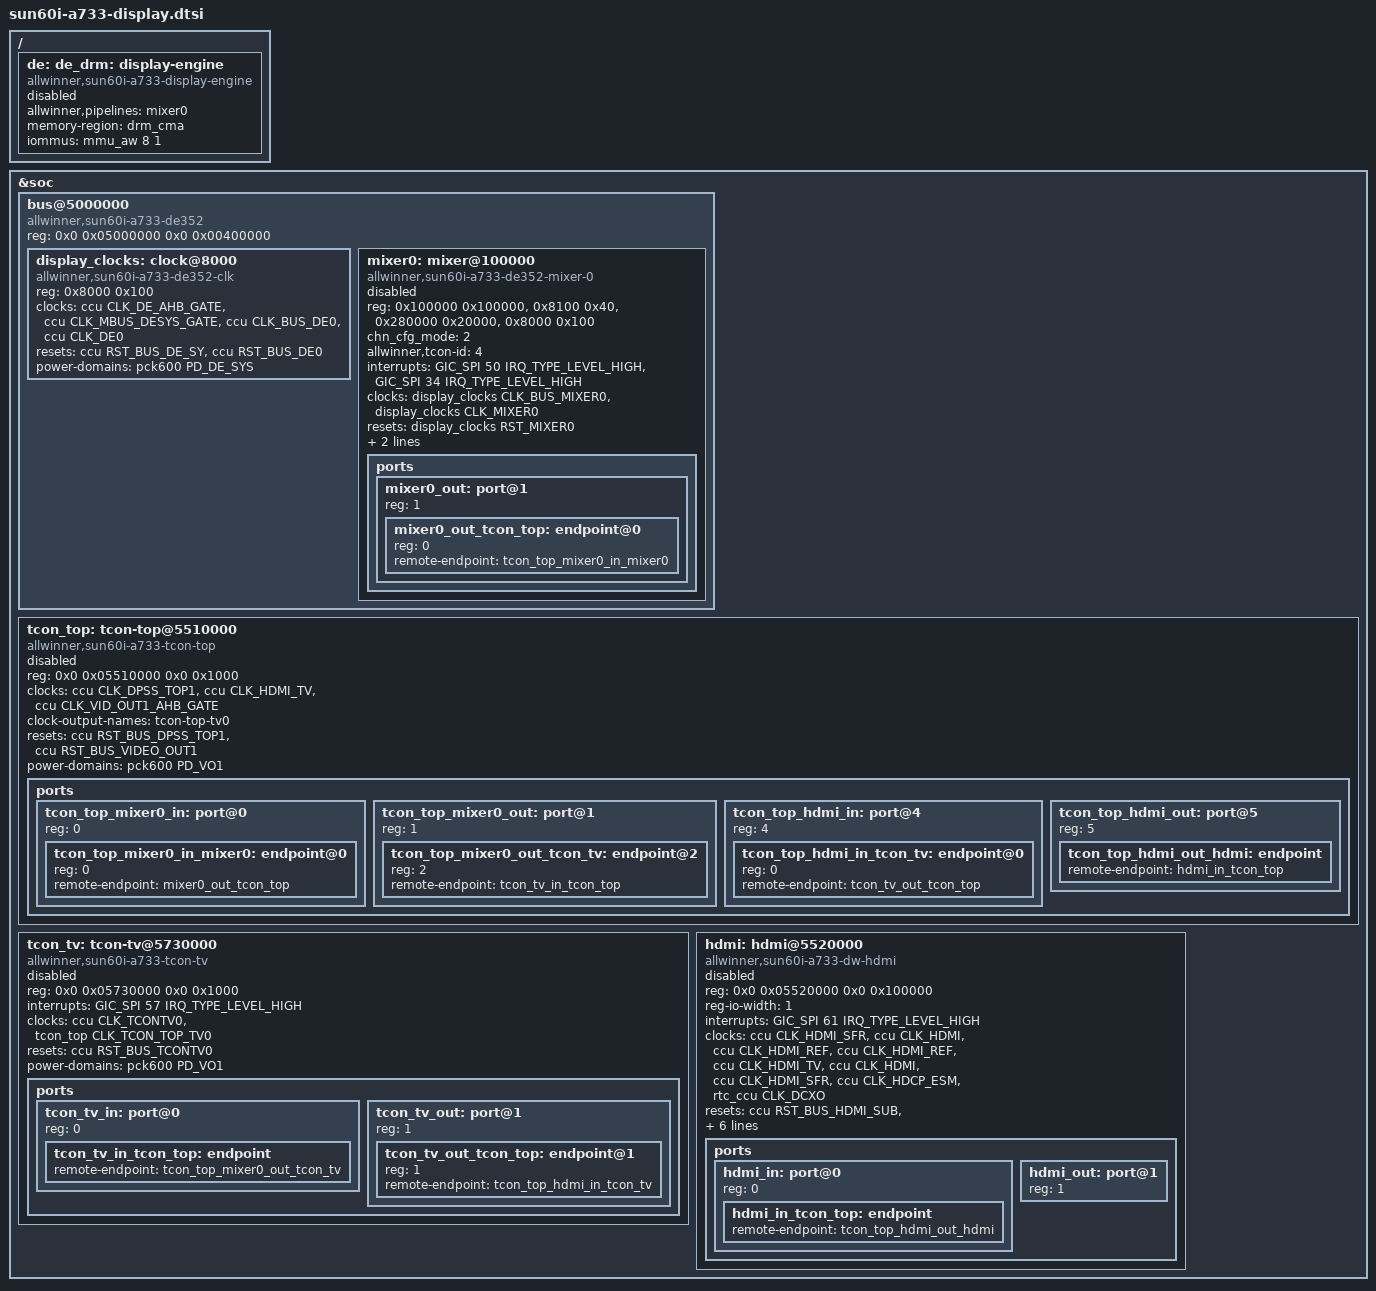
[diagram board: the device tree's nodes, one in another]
// SPDX-License-Identifier: (GPL-2.0-or-later OR MIT)
/* Copyright(c) 2020 - 2023 Allwinner Technology Co.,Ltd. All rights reserved. */

#include <dt-bindings/interrupt-controller/arm-gic.h>
#include <dt-bindings/clock/sun60i-a733-ccu.h>
#include <dt-bindings/reset/sun60i-a733-ccu.h>
#include <dt-bindings/clock/sun60i-a733-rtc.h>
#include <dt-bindings/clock/sun60i-de352.h>
#include <dt-bindings/reset/sun60i-de352.h>
#include <dt-bindings/clock/sun8i-tcon-top.h>
#include <dt-bindings/power/allwinner,sun60i-a733-pck-600.h>

/ {
	de: de_drm: display-engine {
		compatible = "allwinner,sun60i-a733-display-engine";
		allwinner,pipelines = <&mixer0>;
		memory-region = <&drm_cma>;
		iommus = <&mmu_aw 8 1>;
		status = "disabled";
	};
};

&soc {
	bus@5000000 {
		compatible = "allwinner,sun60i-a733-de352", "simple-bus";
		reg = <0x0 0x05000000 0x0 0x00400000>;
		#address-cells = <1>;
		#size-cells = <1>;
		ranges = <0x0 0x0 0x05000000 0x400000>;

		display_clocks: clock@8000 {
			compatible = "allwinner,sun60i-a733-de352-clk";
			reg = <0x8000 0x100>;
			clocks = <&ccu CLK_DE_AHB_GATE>,
				 <&ccu CLK_MBUS_DESYS_GATE>,
				 <&ccu CLK_BUS_DE0>,
				 <&ccu CLK_DE0>;
			clock-names = "ahb", "mbus", "bus", "mod";
			resets = <&ccu RST_BUS_DE_SY>, <&ccu RST_BUS_DE0>;
			reset-names = "sys", "bus";
			power-domains = <&pck600 PD_DE_SYS>;
			#clock-cells = <1>;
			#reset-cells = <1>;
		};

		mixer0: mixer@100000 {
			compatible = "allwinner,sun60i-a733-de352-mixer-0";
			reg = <0x100000 0x100000>,
			      <0x8100 0x40>,
			      <0x280000 0x20000>,
			      <0x8000 0x100>;
			reg-names = "engine", "top", "display", "detop";
			chn_cfg_mode = <2>;
			allwinner,tcon-id = <4>;
			interrupts = <GIC_SPI 50 IRQ_TYPE_LEVEL_HIGH>,
				     <GIC_SPI 34 IRQ_TYPE_LEVEL_HIGH>;
			clocks = <&display_clocks CLK_BUS_MIXER0>,
				 <&display_clocks CLK_MIXER0>;
			clock-names = "bus", "mod";
			resets = <&display_clocks RST_MIXER0>;
			reset-names = "mod";
			iommus = <&mmu_aw 8 1>;
			nsi = <&nsi0 2>;
			status = "disabled";

			ports {
				#address-cells = <1>;
				#size-cells = <0>;

				mixer0_out: port@1 {
					reg = <1>;
					#address-cells = <1>;
					#size-cells = <0>;

					mixer0_out_tcon_top: endpoint@0 {
						reg = <0>;
						remote-endpoint = <&tcon_top_mixer0_in_mixer0>;
					};
				};
			};
		};
	};

	tcon_top: tcon-top@5510000 {
		compatible = "allwinner,sun60i-a733-tcon-top";
		reg = <0x0 0x05510000 0x0 0x1000>;
		clocks = <&ccu CLK_DPSS_TOP1>, <&ccu CLK_HDMI_TV>,
			 <&ccu CLK_VID_OUT1_AHB_GATE>;
		clock-names = "bus", "tcon-tv0", "ahb-gate";
		clock-output-names = "tcon-top-tv0";
		resets = <&ccu RST_BUS_DPSS_TOP1>, <&ccu RST_BUS_VIDEO_OUT1>;
		reset-names = "bus", "rst_bus_reg";
		#clock-cells = <1>;
		power-domains = <&pck600 PD_VO1>;
		status = "disabled";

		ports {
			#address-cells = <1>;
			#size-cells = <0>;

			tcon_top_mixer0_in: port@0 {
				#address-cells = <1>;
				#size-cells = <0>;
				reg = <0>;

				tcon_top_mixer0_in_mixer0: endpoint@0 {
					reg = <0>;
					remote-endpoint = <&mixer0_out_tcon_top>;
				};
			};

			tcon_top_mixer0_out: port@1 {
				#address-cells = <1>;
				#size-cells = <0>;
				reg = <1>;

				tcon_top_mixer0_out_tcon_tv: endpoint@2 {
					reg = <2>;
					remote-endpoint = <&tcon_tv_in_tcon_top>;
				};
			};

			tcon_top_hdmi_in: port@4 {
				#address-cells = <1>;
				#size-cells = <0>;
				reg = <4>;

				tcon_top_hdmi_in_tcon_tv: endpoint@0 {
					reg = <0>;
					remote-endpoint = <&tcon_tv_out_tcon_top>;
				};
			};

			tcon_top_hdmi_out: port@5 {
				reg = <5>;

				tcon_top_hdmi_out_hdmi: endpoint {
					remote-endpoint = <&hdmi_in_tcon_top>;
				};
			};
		};
	};

	tcon_tv: tcon-tv@5730000 {
		compatible = "allwinner,sun60i-a733-tcon-tv";
		reg = <0x0 0x05730000 0x0 0x1000>;
		interrupts = <GIC_SPI 57 IRQ_TYPE_LEVEL_HIGH>;
		clocks = <&ccu CLK_TCONTV0>, <&tcon_top CLK_TCON_TOP_TV0>;
		clock-names = "ahb", "tcon-ch1";
		resets = <&ccu RST_BUS_TCONTV0>;
		reset-names = "lcd";
		power-domains = <&pck600 PD_VO1>;
		status = "disabled";

		ports {
			#address-cells = <1>;
			#size-cells = <0>;

			tcon_tv_in: port@0 {
				reg = <0>;

				tcon_tv_in_tcon_top: endpoint {
					remote-endpoint = <&tcon_top_mixer0_out_tcon_tv>;
				};
			};

			tcon_tv_out: port@1 {
				#address-cells = <1>;
				#size-cells = <0>;
				reg = <1>;

				tcon_tv_out_tcon_top: endpoint@1 {
					reg = <1>;
					remote-endpoint = <&tcon_top_hdmi_in_tcon_tv>;
				};
			};
		};
	};

	hdmi: hdmi@5520000 {
		compatible = "allwinner,sun60i-a733-dw-hdmi";
		#sound-dai-cells = <0>;
		reg = <0x0 0x05520000 0x0 0x100000>;
		reg-io-width = <1>;
		interrupts = <GIC_SPI 61 IRQ_TYPE_LEVEL_HIGH>;
		clocks = <&ccu CLK_HDMI_SFR>, <&ccu CLK_HDMI>, <&ccu CLK_HDMI_REF>,
			 <&ccu CLK_HDMI_REF>, <&ccu CLK_HDMI_TV>, <&ccu CLK_HDMI>,
			 <&ccu CLK_HDMI_SFR>, <&ccu CLK_HDCP_ESM>, <&rtc_ccu CLK_DCXO>;
		clock-names = "isfr", "iahb", "cec",
			      "clk_cec", "clk_tcon_tv", "clk_hdmi", "clk_hdmi_24M",
			      "clk_hdcp", "clk_dcxo";
		resets = <&ccu RST_BUS_HDMI_SUB>, <&ccu RST_BUS_HDMI_MAIN>,
			 <&ccu RST_BUS_HDMI_HDCP>;
		reset-names = "rst_bus_sub", "rst_bus_main", "rst_bus_hdcp";
		assigned-clocks = <&ccu CLK_HDMI>, <&ccu CLK_HDMI_TV>,
				  <&ccu CLK_HDMI_REF>;
		assigned-clock-parents = <0>, <&ccu CLK_PLL_VIDEO0_4X>,
					 <&ccu CLK_HDMI_CEC_32K>;
		power-domains = <&pck600 PD_VO1>;
		status = "disabled";

		ports {
			#address-cells = <1>;
			#size-cells = <0>;

			hdmi_in: port@0 {
				reg = <0>;

				hdmi_in_tcon_top: endpoint {
					remote-endpoint = <&tcon_top_hdmi_out_hdmi>;
				};
			};

			hdmi_out: port@1 {
				reg = <1>;
			};
		};
	};
};
